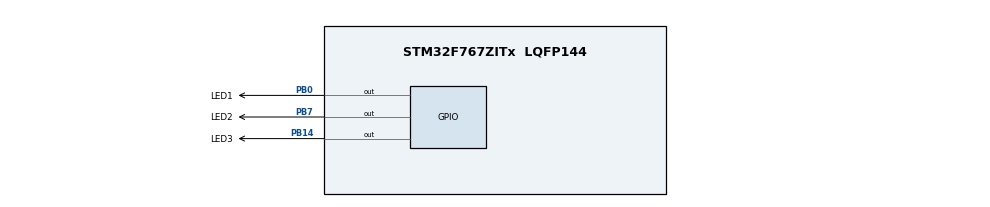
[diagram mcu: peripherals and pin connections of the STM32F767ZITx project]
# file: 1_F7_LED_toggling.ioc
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Mcu.Family=STM32F7
Mcu.Name=STM32F767ZITx
Mcu.Package=LQFP144
NVIC.PriorityGroup=NVIC_PRIORITYGROUP_4
PA13.Mode=Serial_Wire
PA13.Signal=SYS_JTMS-SWDIO
PA14.Mode=Serial_Wire
PA14.Signal=SYS_JTCK-SWCLK
PB0.GPIO_Label=LED1
PB0.GPIO_Speed=GPIO_SPEED_FREQ_LOW
PB0.Signal=GPIO_Output
PB14.GPIO_Label=LED3
PB14.GPIO_Speed=GPIO_SPEED_FREQ_LOW
PB14.Signal=GPIO_Output
PB7.GPIO_FM7=__NULL
PB7.GPIO_Label=LED2
PB7.GPIO_Speed=GPIO_SPEED_FREQ_LOW
PB7.Signal=GPIO_Output
ProjectManager.HeapSize=0x200
ProjectManager.StackSize=0x400
ProjectManager.TargetToolchain=STM32CubeIDE
RCC.HSE_VALUE=25000000
RCC.HSI_VALUE=16000000
RCC.LSE_VALUE=32768
RCC.USBFreq_Value=96000000
RCC.VCOOutputFreq_Value=192000000
board=custom

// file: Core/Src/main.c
/* USER CODE BEGIN Header */
/**
  ******************************************************************************
  * @file           : main.c
  * @brief          : Main program body
  ******************************************************************************
  * @attention
  *
  * Copyright (c) 2024 STMicroelectronics.
  * All rights reserved.
  *
  * This software is licensed under terms that can be found in the LICENSE file
  * in the root directory of this software component.
  * If no LICENSE file comes with this software, it is provided AS-IS.
  *
  ******************************************************************************
  */
/* USER CODE END Header */
#include "main.h"

/* USER CODE BEGIN PTD */
typedef enum
{
	LED1 = 0,
	LED_GREEN = LED1,
	LED2 = 1,
	LED_BLUE = LED2,
	LED3 = 2,
	LED_RED = LED3,
} Led_TypeDef;
/* USER CODE END PTD */

/* USER CODE BEGIN PD */
#define LEDn 3
/* USER CODE END PD */

/* USER CODE BEGIN PV */
GPIO_TypeDef* GPIO_PORT[LEDn] = {LED1_GPIO_Port, LED2_GPIO_Port, LED3_GPIO_Port};
uint16_t GPIO_PIN[LEDn] = {LED1_Pin, LED2_Pin, LED3_Pin};
/* USER CODE END PV */

void SystemClock_Config(void);
static void MX_GPIO_Init(void);
/* USER CODE BEGIN PFP */
void LED_On(Led_TypeDef Led);
void LED_Off(Led_TypeDef Led);
void LED_Toggle(Led_TypeDef Led);
/* USER CODE END PFP */

int main(void)
{

  /* MCU Configuration--------------------------------------------------------*/

  /* Reset of all peripherals, Initializes the Flash interface and the Systick. */
  HAL_Init();

  /* Configure the system clock */
  SystemClock_Config();

  /* Initialize all configured peripherals */
  MX_GPIO_Init();

  /* Infinite loop */
  /* USER CODE BEGIN WHILE */
  while (1)
  {
	  LED_Toggle(LED2);
	  HAL_Delay(100);
    /* USER CODE END WHILE */

  }
}

void SystemClock_Config(void)
{
  RCC_OscInitTypeDef RCC_OscInitStruct = {0};
  RCC_ClkInitTypeDef RCC_ClkInitStruct = {0};

  /** Configure the main internal regulator output voltage
  */
  __HAL_RCC_PWR_CLK_ENABLE();
  __HAL_PWR_VOLTAGESCALING_CONFIG(PWR_REGULATOR_VOLTAGE_SCALE3);

  /** Initializes the RCC Oscillators according to the specified parameters
  * in the RCC_OscInitTypeDef structure.
  */
  RCC_OscInitStruct.OscillatorType = RCC_OSCILLATORTYPE_HSI;
  RCC_OscInitStruct.HSIState = RCC_HSI_ON;
  RCC_OscInitStruct.HSICalibrationValue = RCC_HSICALIBRATION_DEFAULT;
  RCC_OscInitStruct.PLL.PLLState = RCC_PLL_NONE;
  if (HAL_RCC_OscConfig(&RCC_OscInitStruct) != HAL_OK)
  {
    Error_Handler();
  }

  /** Initializes the CPU, AHB and APB buses clocks
  */
  RCC_ClkInitStruct.ClockType = RCC_CLOCKTYPE_HCLK|RCC_CLOCKTYPE_SYSCLK
                              |RCC_CLOCKTYPE_PCLK1|RCC_CLOCKTYPE_PCLK2;
  RCC_ClkInitStruct.SYSCLKSource = RCC_SYSCLKSOURCE_HSI;
  RCC_ClkInitStruct.AHBCLKDivider = RCC_SYSCLK_DIV1;
  RCC_ClkInitStruct.APB1CLKDivider = RCC_HCLK_DIV1;
  RCC_ClkInitStruct.APB2CLKDivider = RCC_HCLK_DIV1;

  if (HAL_RCC_ClockConfig(&RCC_ClkInitStruct, FLASH_LATENCY_0) != HAL_OK)
  {
    Error_Handler();
  }
}

static void MX_GPIO_Init(void)
{
  GPIO_InitTypeDef GPIO_InitStruct = {0};

  /* GPIO Ports Clock Enable */
  __HAL_RCC_GPIOB_CLK_ENABLE();
  __HAL_RCC_GPIOA_CLK_ENABLE();

  /*Configure GPIO pin Output Level */
  HAL_GPIO_WritePin(GPIOB, LED1_Pin|LED3_Pin|LED2_Pin, GPIO_PIN_RESET);

  /*Configure GPIO pins : LED1_Pin LED3_Pin LED2_Pin */
  GPIO_InitStruct.Pin = LED1_Pin|LED3_Pin|LED2_Pin;
  GPIO_InitStruct.Mode = GPIO_MODE_OUTPUT_PP;
  GPIO_InitStruct.Pull = GPIO_NOPULL;
  GPIO_InitStruct.Speed = GPIO_SPEED_FREQ_LOW;
  HAL_GPIO_Init(GPIOB, &GPIO_InitStruct);

}

/* USER CODE BEGIN 4 */
void LED_On(Led_TypeDef Led)
{
	HAL_GPIO_WritePin(GPIO_PORT[Led], GPIO_PIN[Led], GPIO_PIN_SET);
}

void LED_Off(Led_TypeDef Led)
{
	HAL_GPIO_WritePin(GPIO_PORT[Led], GPIO_PIN[Led], GPIO_PIN_RESET);
}

void LED_Toggle(Led_TypeDef Led)
{
	HAL_GPIO_TogglePin(GPIO_PORT[Led], GPIO_PIN[Led]);
}
/* USER CODE END 4 */

void Error_Handler(void)
{
  /* USER CODE BEGIN Error_Handler_Debug */
  /* User can add his own implementation to report the HAL error return state */
	LED_On(LED2);
  __disable_irq();
  while (1)
  {
  }
  /* USER CODE END Error_Handler_Debug */
}
